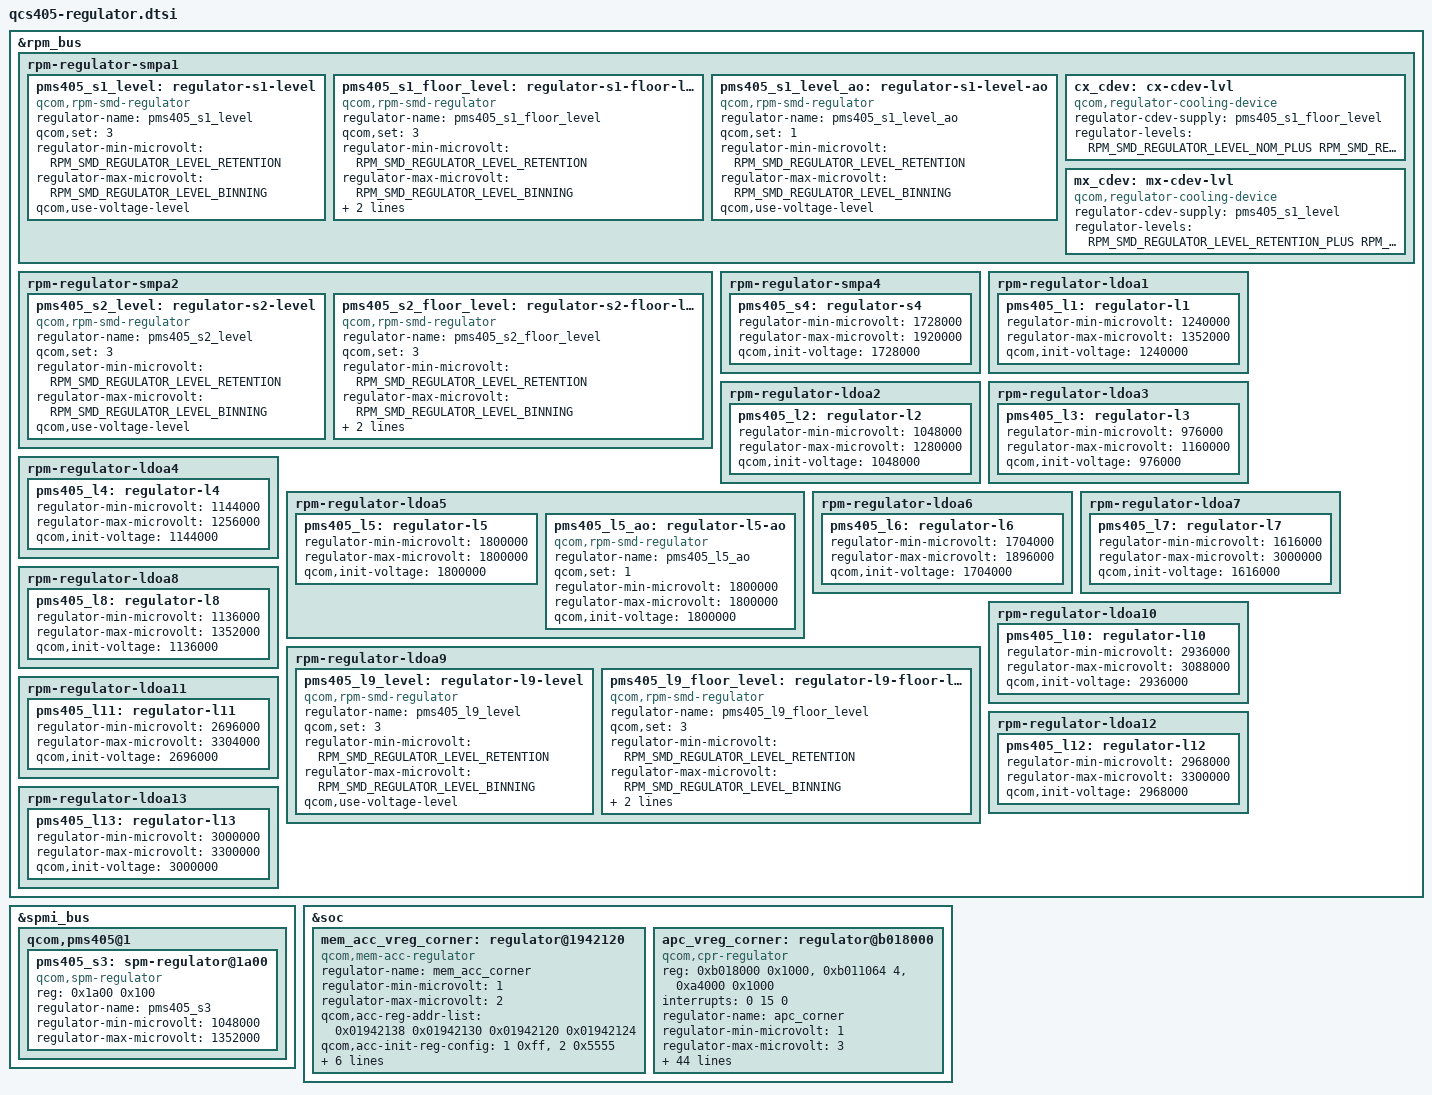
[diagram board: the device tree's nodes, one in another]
/*
 * Copyright (c) 2018, The Linux Foundation. All rights reserved.
 *
 * This program is free software; you can redistribute it and/or modify
 * it under the terms of the GNU General Public License version 2 and
 * only version 2 as published by the Free Software Foundation.
 *
 * This program is distributed in the hope that it will be useful,
 * but WITHOUT ANY WARRANTY; without even the implied warranty of
 * MERCHANTABILITY or FITNESS FOR A PARTICULAR PURPOSE.  See the
 * GNU General Public License for more details.
 */

#include <dt-bindings/interrupt-controller/arm-gic.h>

&rpm_bus {
	/* PMS405 S1 - VDD_MX/CX supply */
	rpm-regulator-smpa1 {
		status = "okay";
		pms405_s1_level: regulator-s1-level {
			compatible = "qcom,rpm-smd-regulator";
			regulator-name = "pms405_s1_level";
			qcom,set = <3>;
			regulator-min-microvolt =
					<RPM_SMD_REGULATOR_LEVEL_RETENTION>;
			regulator-max-microvolt =
					<RPM_SMD_REGULATOR_LEVEL_BINNING>;
			qcom,use-voltage-level;
		};

		pms405_s1_floor_level: regulator-s1-floor-level {
			compatible = "qcom,rpm-smd-regulator";
			regulator-name = "pms405_s1_floor_level";
			qcom,set = <3>;
			regulator-min-microvolt =
					<RPM_SMD_REGULATOR_LEVEL_RETENTION>;
			regulator-max-microvolt =
					<RPM_SMD_REGULATOR_LEVEL_BINNING>;
			qcom,use-voltage-floor-level;
			qcom,always-send-voltage;
		};

		pms405_s1_level_ao: regulator-s1-level-ao {
			compatible = "qcom,rpm-smd-regulator";
			regulator-name = "pms405_s1_level_ao";
			qcom,set = <1>;
			regulator-min-microvolt =
					<RPM_SMD_REGULATOR_LEVEL_RETENTION>;
			regulator-max-microvolt =
					<RPM_SMD_REGULATOR_LEVEL_BINNING>;
			qcom,use-voltage-level;
		};

		cx_cdev: cx-cdev-lvl {
			compatible = "qcom,regulator-cooling-device";
			regulator-cdev-supply = <&pms405_s1_floor_level>;
			regulator-levels = <RPM_SMD_REGULATOR_LEVEL_NOM_PLUS
					RPM_SMD_REGULATOR_LEVEL_NONE>;
			#cooling-cells = <2>;
		};

		mx_cdev: mx-cdev-lvl {
			compatible = "qcom,regulator-cooling-device";
			regulator-cdev-supply = <&pms405_s1_level>;
			regulator-levels =
				<RPM_SMD_REGULATOR_LEVEL_RETENTION_PLUS
					RPM_SMD_REGULATOR_LEVEL_NONE>;
			#cooling-cells = <2>;
		};
	};

	/* PMS405 S2 - VDD_LPI_CX supply */
	rpm-regulator-smpa2 {
		status = "okay";
		pms405_s2_level: regulator-s2-level {
			compatible = "qcom,rpm-smd-regulator";
			regulator-name = "pms405_s2_level";
			qcom,set = <3>;
			regulator-min-microvolt =
					<RPM_SMD_REGULATOR_LEVEL_RETENTION>;
			regulator-max-microvolt =
					<RPM_SMD_REGULATOR_LEVEL_BINNING>;
			qcom,use-voltage-level;
		};

		pms405_s2_floor_level: regulator-s2-floor-level {
			compatible = "qcom,rpm-smd-regulator";
			regulator-name = "pms405_s2_floor_level";
			qcom,set = <3>;
			regulator-min-microvolt =
					<RPM_SMD_REGULATOR_LEVEL_RETENTION>;
			regulator-max-microvolt =
					<RPM_SMD_REGULATOR_LEVEL_BINNING>;
			qcom,use-voltage-floor-level;
			qcom,always-send-voltage;
		};
	};

	rpm-regulator-smpa4 {
		status = "okay";
		pms405_s4: regulator-s4 {
			regulator-min-microvolt = <1728000>;
			regulator-max-microvolt = <1920000>;
			qcom,init-voltage = <1728000>;
			status = "okay";
		};
	};

	rpm-regulator-ldoa1 {
		status = "okay";
		pms405_l1: regulator-l1 {
			regulator-min-microvolt = <1240000>;
			regulator-max-microvolt = <1352000>;
			qcom,init-voltage = <1240000>;
			status = "okay";
		};
	};

	rpm-regulator-ldoa2 {
		status = "okay";
		pms405_l2: regulator-l2 {
			regulator-min-microvolt = <1048000>;
			regulator-max-microvolt = <1280000>;
			qcom,init-voltage = <1048000>;
			status = "okay";
		};
	};

	rpm-regulator-ldoa3 {
		status = "okay";
		pms405_l3: regulator-l3 {
			regulator-min-microvolt = <976000>;
			regulator-max-microvolt = <1160000>;
			qcom,init-voltage = <976000>;
			status = "okay";
		};
	};

	rpm-regulator-ldoa4 {
		status = "okay";
		pms405_l4: regulator-l4 {
			regulator-min-microvolt = <1144000>;
			regulator-max-microvolt = <1256000>;
			qcom,init-voltage = <1144000>;
			status = "okay";
		};
	};

	rpm-regulator-ldoa5 {
		status = "okay";
		pms405_l5: regulator-l5 {
			regulator-min-microvolt = <1800000>;
			regulator-max-microvolt = <1800000>;
			qcom,init-voltage = <1800000>;
			status = "okay";
		};

		pms405_l5_ao: regulator-l5-ao {
			compatible = "qcom,rpm-smd-regulator";
			regulator-name = "pms405_l5_ao";
			qcom,set = <1>;
			regulator-min-microvolt = <1800000>;
			regulator-max-microvolt = <1800000>;
			qcom,init-voltage = <1800000>;
			status = "okay";
		};
	};

	rpm-regulator-ldoa6 {
		status = "okay";
		pms405_l6: regulator-l6 {
			regulator-min-microvolt = <1704000>;
			regulator-max-microvolt = <1896000>;
			qcom,init-voltage = <1704000>;
			status = "okay";
		};
	};

	rpm-regulator-ldoa7 {
		status = "okay";
		pms405_l7: regulator-l7 {
			regulator-min-microvolt = <1616000>;
			regulator-max-microvolt = <3000000>;
			qcom,init-voltage = <1616000>;
			status = "okay";
		};
	};

	rpm-regulator-ldoa8 {
		status = "okay";
		pms405_l8: regulator-l8 {
			regulator-min-microvolt = <1136000>;
			regulator-max-microvolt = <1352000>;
			qcom,init-voltage = <1136000>;
			status = "okay";
		};
	};

	/* PMS405 L9 - VDD_LPI_MX supply */
	rpm-regulator-ldoa9 {
		status = "okay";
		pms405_l9_level: regulator-l9-level {
			compatible = "qcom,rpm-smd-regulator";
			regulator-name = "pms405_l9_level";
			qcom,set = <3>;
			regulator-min-microvolt =
					<RPM_SMD_REGULATOR_LEVEL_RETENTION>;
			regulator-max-microvolt =
					<RPM_SMD_REGULATOR_LEVEL_BINNING>;
			qcom,use-voltage-level;
		};

		pms405_l9_floor_level: regulator-l9-floor-level {
			compatible = "qcom,rpm-smd-regulator";
			regulator-name = "pms405_l9_floor_level";
			qcom,set = <3>;
			regulator-min-microvolt =
					<RPM_SMD_REGULATOR_LEVEL_RETENTION>;
			regulator-max-microvolt =
					<RPM_SMD_REGULATOR_LEVEL_BINNING>;
			qcom,use-voltage-floor-level;
			qcom,always-send-voltage;
		};
	};

	rpm-regulator-ldoa10 {
		status = "okay";
		pms405_l10: regulator-l10 {
			regulator-min-microvolt = <2936000>;
			regulator-max-microvolt = <3088000>;
			qcom,init-voltage = <2936000>;
			status = "okay";
		};
	};

	rpm-regulator-ldoa11 {
		status = "okay";
		pms405_l11: regulator-l11 {
			regulator-min-microvolt = <2696000>;
			regulator-max-microvolt = <3304000>;
			qcom,init-voltage = <2696000>;
			status = "okay";
		};
	};

	rpm-regulator-ldoa12 {
		status = "okay";
		pms405_l12: regulator-l12 {
			regulator-min-microvolt = <2968000>;
			regulator-max-microvolt = <3300000>;
			qcom,init-voltage = <2968000>;
			status = "okay";
		};
	};

	rpm-regulator-ldoa13 {
		status = "okay";
		pms405_l13: regulator-l13 {
			regulator-min-microvolt = <3000000>;
			regulator-max-microvolt = <3300000>;
			qcom,init-voltage = <3000000>;
			status = "okay";
		};
	};
};

&spmi_bus {
	qcom,pms405@1 {
		/* PMS405 S3 = VDD_APC_supply */
		pms405_s3: spm-regulator@1a00 {
			compatible = "qcom,spm-regulator";
			reg = <0x1a00 0x100>;
			regulator-name = "pms405_s3";
			regulator-min-microvolt = <1048000>;
			regulator-max-microvolt = <1352000>;
		};
	};
};

&soc {
	/* APC CPR and MEM ACC regulators */
	mem_acc_vreg_corner: regulator@1942120 {
		compatible = "qcom,mem-acc-regulator";
		regulator-name = "mem_acc_corner";
		regulator-min-microvolt = <1>;
		regulator-max-microvolt = <2>;

		qcom,acc-reg-addr-list =
			<0x01942138 0x01942130 0x01942120 0x01942124>;

		qcom,acc-init-reg-config = <1 0xff>, <2 0x5555>;

		qcom,num-acc-corners = <2>;
		qcom,boot-acc-corner = <2>;
		qcom,corner1-reg-config =
			/* INT2 => INT2 */
			<(-1) (-1)>,     <(-1) (-1)>,
			/* INT2 => NOM */
			<  3 0x0>,       <  4  0x0>;

		qcom,corner2-reg-config =
			/* NOM => INT2 */
			<  3 0x1041041>, <  4  0x41>,
			/* NOM => NOM */
			<(-1) (-1)>,     <(-1) (-1)>;
	};

	apc_vreg_corner: regulator@b018000 {
		compatible = "qcom,cpr-regulator";
		reg = <0xb018000 0x1000>, <0xb011064 4>, <0xa4000 0x1000>;
		reg-names = "rbcpr", "rbcpr_clk", "efuse_addr";
		interrupts = <0 15 0>;
		regulator-name = "apc_corner";
		regulator-min-microvolt = <1>;
		regulator-max-microvolt = <3>;

		qcom,cpr-fuse-corners = <3>;
		qcom,cpr-voltage-ceiling = <1224000 1288000 1352000>;
		qcom,cpr-voltage-floor =   <1048000 1048000 1088000>;
		vdd-apc-supply = <&pms405_s3>;

		mem-acc-supply = <&mem_acc_vreg_corner>;

		qcom,cpr-ref-clk = <19200>;
		qcom,cpr-timer-delay = <5000>;
		qcom,cpr-timer-cons-up = <0>;
		qcom,cpr-timer-cons-down = <2>;
		qcom,cpr-irq-line = <0>;
		qcom,cpr-step-quotient = <25>;
		qcom,cpr-up-threshold = <1>;
		qcom,cpr-down-threshold = <3>;
		qcom,cpr-idle-clocks = <15>;
		qcom,cpr-gcnt-time = <1>;
		qcom,vdd-apc-step-up-limit = <1>;
		qcom,vdd-apc-step-down-limit = <1>;
		qcom,cpr-apc-volt-step = <8000>;

		qcom,cpr-fuse-row = <69 0>;
		qcom,cpr-fuse-target-quot = <30 42 64>;
		qcom,cpr-fuse-ro-sel = <0 4 8>;
		qcom,cpr-init-voltage-ref = <1224000 1288000 1352000>;
		qcom,cpr-fuse-init-voltage =
					<69 12 6 0>,
					<69 18 6 0>,
					<69 24 6 0>;
		qcom,cpr-fuse-quot-offset =
					<70 12 7 0>,
					<70 19 7 0>,
					<70 26 7 0>;
		qcom,cpr-fuse-quot-offset-scale = <5 5 5>;
		qcom,cpr-init-voltage-step = <8000>;
		qcom,cpr-corner-map = <1 2 3>;
		qcom,mem-acc-corner-map = <1 2 2>;
		qcom,cpr-corner-frequency-map =
				<1 1094400000>,
				<2 1248000000>,
				<3 1401600000>;
		qcom,speed-bin-fuse-sel = <39 34 3 0>;
		qcom,cpr-fuse-revision = <67 3 3 0>;
		qcom,cpr-speed-bin-max-corners =
					<(-1) (-1) 1 2 3>;
		qcom,cpr-quot-adjust-scaling-factor-max = <0 1400 1400>;
		qcom,cpr-voltage-scaling-factor-max = <0 2000 2000>;
		qcom,cpr-scaled-init-voltage-as-ceiling;
	};
};
